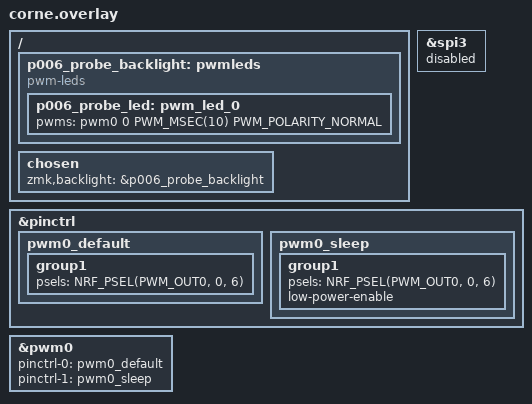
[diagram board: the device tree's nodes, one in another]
#include <zephyr/dt-bindings/pwm/pwm.h>

/* Direct electrical probe for P0.06.
 * Disable the WS2812 SPI peripheral and drive the same pin with PWM0 instead.
 * 100% backlight should read near VCC; 0% should read near GND.
 */
&spi3 {
    status = "disabled";
};

&pinctrl {
    pwm0_default: pwm0_default {
        group1 {
            psels = <NRF_PSEL(PWM_OUT0, 0, 6)>;
        };
    };

    pwm0_sleep: pwm0_sleep {
        group1 {
            psels = <NRF_PSEL(PWM_OUT0, 0, 6)>;
            low-power-enable;
        };
    };
};

&pwm0 {
    status = "okay";
    pinctrl-0 = <&pwm0_default>;
    pinctrl-1 = <&pwm0_sleep>;
    pinctrl-names = "default", "sleep";
};

/ {
    p006_probe_backlight: pwmleds {
        compatible = "pwm-leds";

        p006_probe_led: pwm_led_0 {
            pwms = <&pwm0 0 PWM_MSEC(10) PWM_POLARITY_NORMAL>;
        };
    };

    chosen {
        zmk,backlight = &p006_probe_backlight;
    };
};
